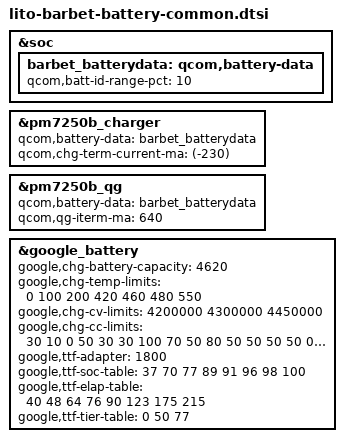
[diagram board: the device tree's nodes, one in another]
// SPDX-License-Identifier: GPL-2.0
/* Copyright (c) 2019, The Linux Foundation. All rights reserved.
 *
 * This program is free software; you can redistribute it and/or modify
 * it under the terms of the GNU General Public License version 2 and
 * only version 2 as published by the Free Software Foundation.
 *
 * This program is distributed in the hope that it will be useful,
 * but WITHOUT ANY WARRANTY; without even the implied warranty of
 * MERCHANTABILITY or FITNESS FOR A PARTICULAR PURPOSE.  See the
 * GNU General Public License for more details.
 */
#include "lito-redbull-battery.dtsi"

&soc {
	barbet_batterydata: qcom,battery-data {
		qcom,batt-id-range-pct = <10>;
		#include "batterydata-qcom-b9-ATL-4620.dtsi"
		#include "batterydata-qcom-b9-LWN-4620.dtsi"
		#include "batterydata-qcom-b9-unknown.dtsi"
		#include "batterydata-qcom-b5-Desay-ATL-3800.dtsi"
		#include "batterydata-qcom-b5-Desay-COS-3800.dtsi"
		#include "batterydata-qcom-b5-Desay-ATL-3750.dtsi"
		#include "batterydata-qcom-b5m-Desay-ATL-3800.dtsi"
		#include "batterydata-qcom-b5m-Desay-COS-3800.dtsi"
		#include "batterydata-qcom-s5-SWD-ATL.dtsi"
		#include "batterydata-qcom-s5-SWD-LSN.dtsi"
	};
};

&pm7250b_charger {
	qcom,battery-data = <&barbet_batterydata>;
	qcom,chg-term-current-ma = <(-230)>;
};

&pm7250b_qg {
	qcom,battery-data = <&barbet_batterydata>;
	qcom,qg-iterm-ma = <640>;
};

&google_battery {
	google,chg-battery-capacity = <4620>;

	/* charge table for barbet */
	google,chg-temp-limits = <0 100 200 420 460 480 550>;
	google,chg-cv-limits = <4200000 4300000 4450000>;
	google,chg-cc-limits = <
		 30  10   0
		 50  30  30
		100  70  50
		 80  50  50
		 50  50   0
		 30   0   0
	>;

	google,ttf-adapter = <1800>;
	google,ttf-soc-table =  <37 70 77 89 91 96  98  100>;
	google,ttf-elap-table = <40 48 64 76 90 123 175 215 >;
	google,ttf-tier-table = <0 50 77>;
};
